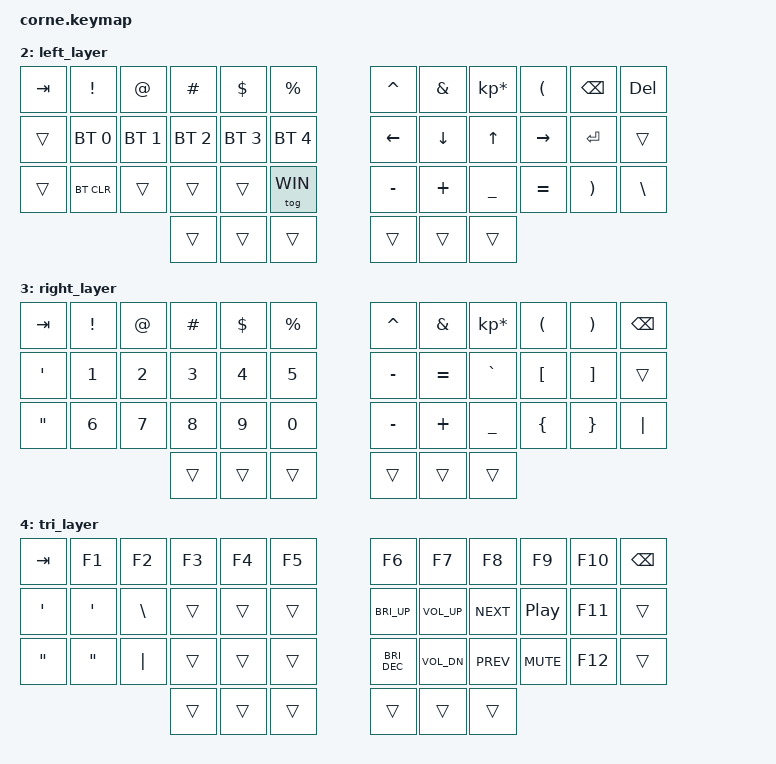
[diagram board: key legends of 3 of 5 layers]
/*
 * Copyright (c) 2020 The ZMK Contributors
 *
 * SPDX-License-Identifier: MIT
 */

#include <behaviors.dtsi>
#include <dt-bindings/zmk/keys.h>
#include <dt-bindings/zmk/bt.h>
//#include <dt-bindings/zmk/outputs.h>

// Home row mods macro
// ----MacOS----
// CAGS--SGAC
#define MAC_HRML(k1,k2,k3,k4) &ht LCTRL k1  &ht LALT k2  &ht LGUI k3  &ht LSHFT k4
#define MAC_HRMR(k1,k2,k3,k4) &ht RSHFT k1  &ht RGUI k2  &ht RALT k3  &ht RCTRL k4

// ----Windows----
// GACS--SCAG
#define WIN_HRML(k1,k2,k3,k4) &ht LGUI k1  &ht LALT k2   &ht LCTRL k3  &ht LSHFT k4
#define WIN_HRMR(k1,k2,k3,k4) &ht RSHFT k1 &ht RCTRL k2  &ht RALT k3   &ht RGUI k4

#define MAC 0
#define WIN 1
#define LEF 2
#define RIG 3
#define TRI 4

/ {
    behaviors {
        ht: hold_tap {
            label = "hold_tap";
            compatible = "zmk,behavior-hold-tap";
            #binding-cells = <2>;
            flavor = "tap-preferred";
            tapping-term-ms = <250>;
            quick-tap-ms = <125>;
            global-quick-tap;
            bindings = <&kp>, <&kp>;
        };
    };

    conditional_layers {
        compatible = "zmk,conditional-layers";
        tri_layer {
            if-layers = <RIG LEF>;
            then-layer = <TRI>;
        };
    };

    keymap {
        compatible = "zmk,keymap";

        //layer 0
        default_layer {
            bindings = <
        //╭──────────┬──────────┬──────────┬─────────┬─────────┬─────────╮   ╭─────────┬──────────┬──────────┬──────────┬─────────┬──────────╮
        //|   ESC    │    Q     │    W     │    E    │    R    │    T    │   │    Y    │    U     │    I     │    O     │    P    │   BKSP   |
            &kp ESC     &kp Q      &kp W      &kp E     &kp R      &kp T         &kp Y    &kp U      &kp I     &kp O       &kp P    &kp BSPC
        //├──────────┼──────────┼──────────┼─────────┼─────────┼─────────┤   ├─────────┼──────────┼──────────┼──────────┼─────────┼──────────┤
        //|   CTRL   │    A     │    S     │    D    │    F    │    G    │   │    H    │    J     │    K     │    L     │    ;:   |   ENT    |
            &kp LCTRL MAC_HRML(A,    S,         D,        F)    &lt LEF G     &lt RIG H MAC_HRMR(J,    K,         L,       SEMI)    &kp RET
        //├──────────┼──────────┼──────────┼─────────┼─────────┼─────────┤   ├─────────┼──────────┼──────────┼──────────┼─────────┼──────────┤
        //|   SHFT   |    Z     │    X     │    C    │    V    │    B    │   │    N    │    M     │   , <    │   . >    │    /?   |   SHFT   |
            &kp LSHFT   &kp Z      &kp X      &kp C     &kp V     &kp B         &kp N     &kp M     &kp COMMA   &kp DOT   &kp FSLH  &kp RSHFT
        //╰──────────┴──────────┴──────────┼─────────┼─────────┼─────────┤   ├─────────┼──────────┼──────────┼──────────┴─────────┴──────────╯
        //                                 |   GUI   |LEFT/ESC |   ENT   |   |   SPC   |RIGHT/TAB |   ALT    |
                                            &kp LGUI &lt LEF ESC &kp RET      &kp SPACE &lt RIG TAB  &kp RALT
        //                                 ╰─────────┴─────────┴─────────╯   ╰─────────┴──────────┴──────────╯
            >;
        };

        //layer 1
        windows_layer {
            bindings = <
        //╭──────────┬──────────┬──────────┬─────────┬─────────┬─────────╮   ╭─────────┬──────────┬──────────┬──────────┬─────────┬──────────╮
        //|   ESC    │    Q     │    W     │    E    │    R    │    T    │   │    Y    │    U     │    I     │    O     │    P    │   BKSP   |
            &kp ESC     &kp Q      &kp W      &kp E     &kp R      &kp T         &kp Y    &kp U      &kp I     &kp O       &kp P    &kp BSPC
        //├──────────┼──────────┼──────────┼─────────┼─────────┼─────────┤   ├─────────┼──────────┼──────────┼──────────┼─────────┼──────────┤
        //|   CTRL   │    A     │    S     │    D    │    F    │    G    │   │    H    │    J     │    K     │    L     │    ;:   |   ENT    |
            &kp LCTRL WIN_HRML(A,    S,         D,        F)    &lt LEF G     &lt RIG H WIN_HRMR(J,    K,         L,       SEMI)    &kp RET
        //├──────────┼──────────┼──────────┼─────────┼─────────┼─────────┤   ├─────────┼──────────┼──────────┼──────────┼─────────┼──────────┤
        //|   SHFT   |    Z     │    X     │    C    │    V    │    B    │   │    N    │    M     │   , <    │   . >    │    /?   |   SHFT   |
            &kp LSHFT   &kp Z      &kp X      &kp C     &kp V     &kp B         &kp N     &kp M     &kp COMMA   &kp DOT   &kp FSLH  &kp RSHFT
        //╰──────────┴──────────┴──────────┼─────────┼─────────┼─────────┤   ├─────────┼──────────┼──────────┼──────────┴─────────┴──────────╯
        //                                 |   GUI   |LEFT/ESC |   ENT   |   |   SPC   |RIGHT/TAB |   ALT    |
                                            &kp LGUI &lt LEF ESC &kp RET      &kp SPACE &lt RIG TAB  &kp RALT
        //                                 ╰─────────┴─────────┴─────────╯   ╰─────────┴──────────┴──────────╯
            >;
        };

        //layer 2
        left_layer {
        //╭──────────┬──────────┬──────────┬─────────┬─────────┬─────────╮   ╭─────────┬──────────┬──────────┬──────────┬─────────┬──────────╮
        //|   TAB    |    !     |    @     |    #    |    $    |    %    |   |    ^    |    &     |    *     |    (     |   BKSP  |   DEL    |
        //├──────────┼──────────┼──────────┼─────────┼─────────┼─────────┤   ├─────────┼──────────┼──────────┼──────────┼─────────┼──────────┤
        //|   CTRL   |   BT1    |   BT2    |   BT3   |   BT4   |   BT5   |   |   LFT   |   DWN    |    UP    |   RGT    |   ENT   |   ENT    |
        //├──────────┼──────────┼──────────┼─────────┼─────────┼─────────┤   ├─────────┼──────────┼──────────┼──────────┼─────────┼──────────┤
        //|          |   BTC    |          |         |         | WINDOWS |   |    -    |    +     |    _     |    =     |    )    |    \     |
        //╰──────────┴──────────┴──────────┼─────────┼─────────┼─────────┤   ├─────────┼──────────┼──────────┼──────────┴─────────┴──────────╯
        //                                 |   GUI   |LEFT/ESC |   ENT   |   |   SPC   |RIGHT/TAB |   ALT    |
        //                                 ╰─────────┴─────────┴─────────╯   ╰─────────┴──────────┴──────────╯
            bindings = <
            &kp TAB    &kp EXCL      &kp AT       &kp HASH     &kp DLLR     &kp PRCNT      &kp CARET  &kp AMPS  &kp KP_MULTIPLY &kp LPAR   &kp BSPC  &kp DELETE
            &trans     &bt BT_SEL 0  &bt BT_SEL 1 &bt BT_SEL 2 &bt BT_SEL 3 &bt BT_SEL 4   &kp LEFT   &kp DOWN  &kp UP          &kp RIGHT  &kp RET   &trans
            &trans     &bt BT_CLR    &trans       &trans       &trans       &tog WIN       &kp MINUS  &kp PLUS  &kp UNDERSCORE  &kp EQUAL  &kp RPAR  &kp BSLH
                                                  &trans       &trans       &trans         &trans     &trans    &trans 
            >;
        };

        //layer 3
        right_layer {
        //╭──────────┬──────────┬──────────┬─────────┬─────────┬─────────╮   ╭─────────┬──────────┬──────────┬──────────┬─────────┬──────────╮
        //|   TAB    |    !     |    @     |    #    |    $    |    %    |   |    ^    |    &     |    *     |    (     |    )    |   BKSP   |
        //├──────────┼──────────┼──────────┼─────────┼─────────┼─────────┤   ├─────────┼──────────┼──────────┼──────────┼─────────┼──────────┤
        //|    '     |    1     |    2     |    3    |    4    |    5    |   |    -    |    =     |    `     |    [     |    ]    |   ENT    |
        //├──────────┼──────────┼──────────┼─────────┼─────────┼─────────┤   ├─────────┼──────────┼──────────┼──────────┼─────────┼──────────┤
        //|    "     |    6     |    7     |    8    |    9    |    0    |   |    -    |    +     |    _     |    {     |    }    |    |     |
        //╰──────────┴──────────┴──────────┼─────────┼─────────┼─────────┤   ├─────────┼──────────┼──────────┼──────────┴─────────┴──────────╯
        //                                 |   GUI   |LEFT/ESC |   ENT   |   |   SPC   |RIGHT/TAB |   ALT    |
        //                                 ╰─────────┴─────────┴─────────╯   ╰─────────┴──────────┴──────────╯            
        bindings = <
            &kp TAB   &kp EXCL &kp AT   &kp HASH  &kp DLLR  &kp PRCNT           &kp CARET  &kp AMPS  &kp KP_MULTIPLY &kp LPAR &kp RPAR &kp BSPC
            &kp SQT   &kp N1   &kp N2   &kp N3    &kp N4    &kp N5              &kp MINUS  &kp EQUAL &kp GRAVE       &kp LBKT &kp RBKT &trans
            &kp DQT   &kp N6   &kp N7   &kp N8    &kp N9    &kp N0              &kp MINUS  &kp PLUS  &kp UNDERSCORE  &kp LBRC &kp RBRC &kp PIPE
                                        &trans    &trans    &trans              &trans     &trans    &trans 
            >;
        };

        //layer 4
        tri_layer {
        //╭──────────┬──────────┬──────────┬─────────┬─────────┬─────────╮   ╭─────────┬──────────┬──────────┬──────────┬─────────┬──────────╮
        //|   TAB    |    F1    |    F2    |    F3   |    F4   |    F5   |   |    F6   |    F7    |    F8    |    F9    |   F10   |   BKSP   |
        //├──────────┼──────────┼──────────┼─────────┼─────────┼─────────┤   ├─────────┼──────────┼──────────┼──────────┼─────────┼──────────┤
        //|    '     |    '     |    \     |         |         |         |   | BRIGHT+ |   VOL+   | NEXTSONG |PAUSEMUSIC|   F11   |          |
        //├──────────┼──────────┼──────────┼─────────┼─────────┼─────────┤   ├─────────┼──────────┼──────────┼──────────┼─────────┼──────────┤
        //|    "     |    "     |    |     |         |         |         |   | BRIGHT- |   VOL-   | PREVSONG | VOL MUTE |   F12   |          |
        //╰──────────┴──────────┴──────────┼─────────┼─────────┼─────────┤   ├─────────┼──────────┼──────────┼──────────┴─────────┴──────────╯
        //                                 |   GUI   |LEFT/ESC |   ENT   |   |   SPC   |RIGHT/TAB |   ALT    |
        //                                 ╰─────────┴─────────┴─────────╯   ╰─────────┴──────────┴──────────╯   
        bindings = <
            &kp TAB   &kp F1   &kp F2     &kp F3    &kp F4    &kp F5            &kp F6          &kp F7          &kp F8        &kp F9       &kp F10   &kp BSPC
            &kp SQT   &kp SQT  &kp BSLH   &trans    &trans    &trans            &kp C_BRI_UP    &kp C_VOL_UP    &kp C_NEXT    &kp C_PP     &kp F11   &trans
            &kp DQT   &kp DQT  &kp PIPE   &trans    &trans    &trans            &kp C_BRI_DEC   &kp C_VOL_DN    &kp C_PREV    &kp C_MUTE   &kp F12   &trans
                                          &trans    &trans    &trans            &trans          &trans          &trans 
            >;
        };
    };
};
